# A31C12x register map
Vendor: ABOV Semiconductor Co., Ltd.; File version: 1.0
CPU: CM0PLUS r0p1, little endian, no MPU, no FPU, VTOR, 2 interrupt priority bits
Registers are 32-bit, read-write, reset 0x0 unless marked. A register's access mark holds for its fields unless they carry their own. Offsets are from the block's base; [hi:lo] are bit positions; {n}, {i} and the like mark numbered series.

## FRT — Free Run Timer
Base 0x40000600
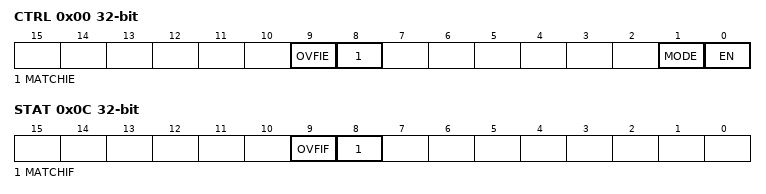
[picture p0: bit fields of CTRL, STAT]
0x00 CTRL — FRT control register
  [9] OVFIE — Whether to enable or disable the FRT counter overflow interrupt in Free-run timer mode (MODE = 0)
    0=Disable (Interrupt Disable); 1=Enable (Interrupt Enable)
  [8] MATCHIE — Whether to enable or disable the FRT counter match interrupt in Periodic timer mode (MODE = 1)
    0=Disable (Interrupt Disable); 1=Enable (Interrupt Enable)
  [1] MODE — FRT mode selection
    0=Free-Run_Timer; 1=Periodic_Timer
  [0] EN — Whether to enable or disable the FRT
    0=Disable (FRT Disable); 1=Enable (FRT Enable)
0x04 MCNT reset 0xFFFFFFFF — FRT match counter register
  [31:0] MCNT — FRTs match counter value
0x08 CNT — FRT counter register
  [31:0] CNT — FRT count data
0x0C STAT — FRT status register
  [9] OVFIF — FRT counter overflow interrupt flag
  [8] MATCHIF — FRT counter match interrupt flag

## UART0 — Universal Asynchronous Receiver/Transmitter 0
Base 0x40008000
0x00 RBR ro — UART n receive data buffer register
  [7:0] RBR — Receive buffer register
0x00 THR wo — UART n transmit data hold register
  [7:0] THR — Transmit data hold register
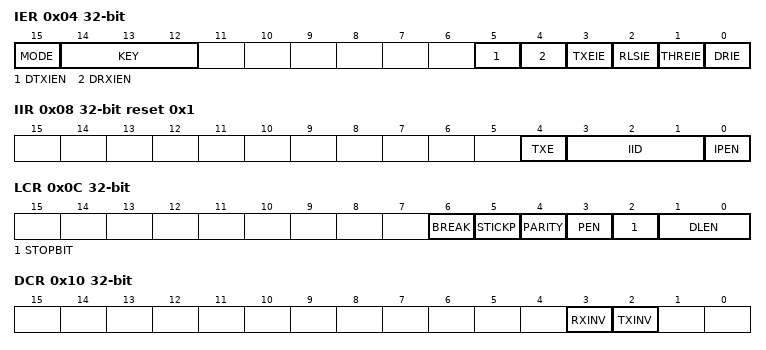
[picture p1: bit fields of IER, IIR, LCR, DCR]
0x04 IER — UART n interrupt enable register
  [15] MODE — Enable or disable IIR extended mode bit
    0=legacy (IIR legacy mode); 1=extended (IIR extended mode)
  [14:12] KEY — Mode change key (0x05)
  [5] DTXIEN — Whether to enable or disable the DMA transmit complete interrupt
  [4] DRXIEN — Whether to enable or disable the DMA receive complete interrupt
  [3] TXEIE — Whether to enable or disable the transmit complete interrupt
  [2] RLSIE — Whether to enable or disable the receive line status interrupt
  [1] THREIE — Whether to enable or disable the transmit data hold register empty (THRE) interrupt
  [0] DRIE — Whether to enable or disable the data receive interrupt
0x08 IIR ro reset 0x1 — UART n interrupt ID register
  [4] TXE — Transmit complete
  [3:1] IID — Interrupt source ID
  [0] IPEN — Presence of pending interrupts
0x0C LCR — UART n line control register
  [6] BREAK — When this bit is set to 1, the TXD pin is driven low to alert the receiver
  [5] STICKP — Whether or not to use stick parity. The setting of this bit is valid only when the PEN bit is set to 1
  [4] PARITY — Parity mode selection
  [3] PEN — Whether or not to enable parity
  [2] STOPBIT — The number of stop bits demanded by the preceding data bits
  [1:0] DLEN — The length of data bits included by each data transfer
    {v}={v+5}bit data (v=0..3)
0x10 DCR — UART n data control register
  [3] RXINV — Rx data inversion selection
  [2] TXINV — Tx data inversion selection
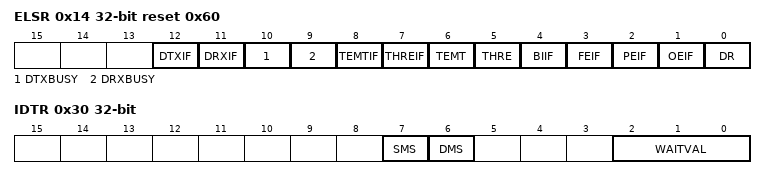
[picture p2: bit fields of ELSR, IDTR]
0x14 ELSR reset 0x60 — UART n line status register
  [12] DTXIF — DMA Transmit complete interrupt flag
  [11] DRXIF — DMA Receiver complete interrupt flag
  [10] DTXBUSY ro — DMA transmit busy check (DTXBUSY indicates whether or not the DMA transmit data is busy)
  [9] DRXBUSY ro — DMA receive busy check (DRXBUSY indicates whether or not the DMA receive data is busy)
  [8] TEMTIF — Transmit complete interrupt flag
  [7] THREIF — Transmit data hold register empty flag
  [6] TEMT ro — Indicates the transmit registers are empty
  [5] THRE ro — Indicates the transmit data hold register is empty
  [4] BIIF — Indicates a break condition has been detected flag
  [3] FEIF — Indicates presence of a frame error flag
  [2] PEIF — Indicates presence of a parity error flag
  [1] OEIF — Indicates presence of an overrun error flag
  [0] DR ro — Indicates data reception status
0x20 BDR — UART n baud-rate divisor latch register
  [15:0] BDR — Baud-rate divisor latch (1 to 65535)
0x24 BFR — UART n baud-rate fraction counter register
  [7:0] BFR — Whether to enable or disable the fraction counter to compensate error from the integer baud-rate divisor
0x30 IDTR — UARTn Inter-frame Delay Time Register
  [7] SMS — Whether to enable or disable multi-sampling the start bit
  [6] DMS — Whether to enable or disable multi-sampling each data bit
  [2:0] WAITVAL — Defines the wait time for the next data frame. [unit: 1-bit period]

## I2C0 — Inter-Integrated Circuit
Base 0x4000A000
Same registers: I2C1 0x4000A100
0x00 DR reset 0xFF — I2C data register
  [7:0] ICDR — In transmit mode, the data stored in this register is outputted from pin SDA in the serial data line. In receive mode, data received at pin SDA is stored in this register; hence, the stored data is loaded by reading this register
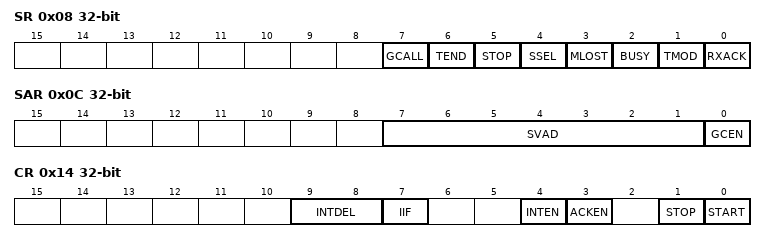
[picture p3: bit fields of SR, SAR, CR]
0x08 SR — I2C status register
  [7] GCALL — This bit signifies different things, depending on whether the I2C is in master or slave mode.
  [6] TEND — One-byte transmit end flag
  [5] STOP — Stop flag
  [4] SSEL — Slave flag
  [3] MLOST — Mastership loss flag
  [2] BUSY ro — Bus busy flag
  [1] TMOD ro — Transmit / receive mode flag
  [0] RXACK — Rx ACK flag
0x0C SAR — I2C slave address register
  [7:1] SVAD — 7-bit slave address
  [0] GCEN — Whether to enable or disable general call
0x14 CR — I2C Control Register
  [9:8] INTDEL — Internal delay between address and data transfers (Or between two data transfers)
    0=1_ICnSCLL (Delay = 1*ICnSCLL); 1=2_ICnSCLL (Delay = 2*ICnSCLL); 2=4_ICnSCLL (Delay = 4*ICnSCLL); 3=8_ICnSCLL (Delay = 8*ICnSCLL)
  [7] IIF ro — Interrupt flag
  [4] INTEN — Whether to enable or disable interrupts
  [3] ACKEN — Whether to enable or disable ACK in receive mode
  [1] STOP — Whether to enable or disable stop
  [0] START — Transmission start in master mode
0x18 SCLL reset 0xFFFF — I2C SCL low duration register
  [15:0] SCLL — SCL low duration value
0x1C SCLH reset 0xFFFF — I2C SCL high duration register
  [15:0] SCLH — SCL high duration value
0x20 SDH reset 0x7FFF — I2C SDA hold register
  [14:0] SDH — SDA hold time value

## CRC — Cyclic Redundancy Check calculation module
Base 0x40082000
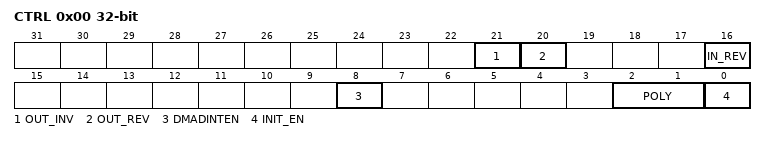
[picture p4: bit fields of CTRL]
0x00 CTRL — CRC control register
  [21] OUT_INV — Whether to enable or disable CRC output data inversion
  [20] OUT_REV — Reverse CRC output data
  [16] IN_REV — Reverse CRC input data
  [8] DMADINTEN — Whether to enable or disable the DMA done interrupt
  [2:1] POLY — Polynomial selection bit
    0=CRC32 (CRC32 (0x04C1_1DB7)); 1=CRC16_USB (CRC16_USB (0x8005)); 2=CRC16_CCITT (CRC16_CCITT (0x1021)); 3=CRC8_CCITT (CRC8_CCITT (0x07))
  [0] INIT_EN wo — Whether or not to apply the CRC initial value register (auto clear)
0x04 INIT reset 0xFFFFFFFF — CRC Init Data Register
  [31:0] INIT_EN — CRC Initial Value
0x08 IDR wo — CRC Input Data Register
  [31:0] IDR — CRC input data bits
0x08 ODR ro reset 0xFFFFFFFF — CRC Output Data Register
  [31:0] ODR — CRC output data bits
0x0C STAT — CRC Status Register
  [8] DMADINT — DMA Done Interrupt Flag Bit

## DBGMCU — Debug MCU Control Register
Base 0x4000F020
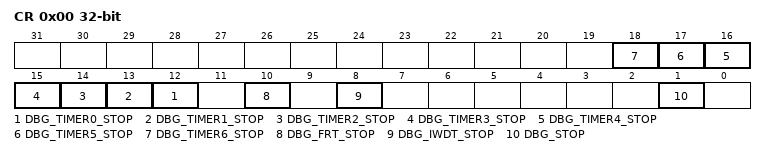
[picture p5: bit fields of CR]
0x00 CR — Debug MCU Register
  [n+12] DBG_TIMER{n}_STOP (n=0..6) — Debug TIMER{n} stopped when core is halted
  [10] DBG_FRT_STOP — Debug FRT stopped when core is halted.
  [8] DBG_IWDT_STOP — Debug independent watchdog stopped when core is halted.
  [1] DBG_STOP — Debug stop mode.
